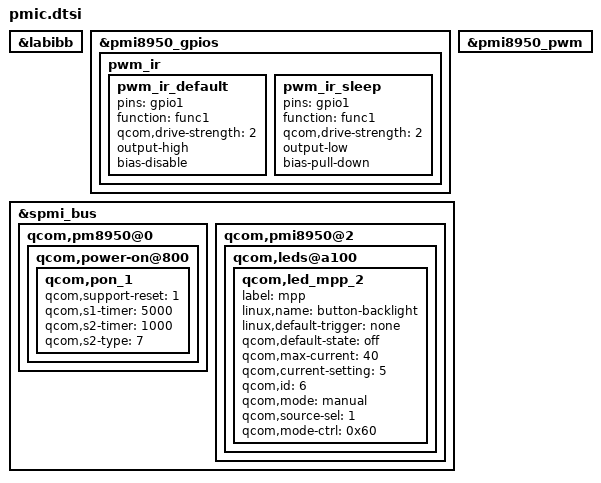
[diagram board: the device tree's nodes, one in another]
&labibb {
	status = "ok";
};

&pmi8950_gpios {
	pwm_ir {
		pwm_ir_default: pwm_ir_default {
			pins = "gpio1";
			function = "func1";
			qcom,drive-strength = <2>;
			output-high;
			bias-disable;
			status = "okay";
		};

		pwm_ir_sleep: pwm_ir_sleep {
			pins = "gpio1";
			function = "func1";
			qcom,drive-strength = <2>;
			output-low;
			bias-pull-down;
			status = "okay";
		};
	};
};

&pmi8950_pwm {
	status = "okay";
};

&spmi_bus {
	qcom,pm8950@0 {
		qcom,power-on@800 {
			qcom,pon_1 {
                qcom,support-reset = <1>;
				qcom,s1-timer = <5000>;
				qcom,s2-timer = <1000>;
				qcom,s2-type = <7>;
			};
		};
	};

	qcom,pmi8950@2 {
		qcom,leds@a100 {
			status = "okay";
			qcom,led_mpp_2 {
				label = "mpp";
				linux,name = "button-backlight";
				linux,default-trigger = "none";
				qcom,default-state = "off";
				qcom,max-current = <40>;
				qcom,current-setting = <5>;
				qcom,id = <6>;
				qcom,mode = "manual";
				qcom,source-sel = <1>;
				qcom,mode-ctrl = <0x60>;
			};
		};
	};
};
